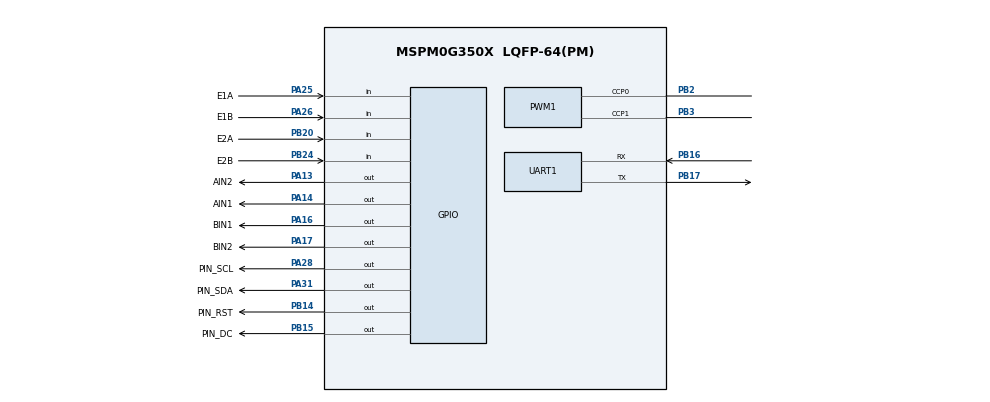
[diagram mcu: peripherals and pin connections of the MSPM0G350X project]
/**
 *
 * @cliArgs --device "MSPM0G350X" --part "Default" --package "LQFP-64(PM)" --product "mspm0_sdk@2.10.00.04"
 * @versions {"tool":"1.28.0+4696"}
 */

/**
 * Import the modules used in this configuration.
 */
const ADC12   = scripting.addModule("/ti/driverlib/ADC12", {}, false);
const ADC121  = ADC12.addInstance();
const DMA     = scripting.addModule("/ti/driverlib/DMA");
const GPIO    = scripting.addModule("/ti/driverlib/GPIO", {}, false);
const GPIO1   = GPIO.addInstance();
const GPIO2   = GPIO.addInstance();
const GPIO3   = GPIO.addInstance();
const GPIO4   = GPIO.addInstance();
const GPIO5   = GPIO.addInstance();
const GPIO6   = GPIO.addInstance();
const GPIO7   = GPIO.addInstance();
const GPIO8   = GPIO.addInstance();
const GPIO9   = GPIO.addInstance();
const GPIO10  = GPIO.addInstance();
const PWM     = scripting.addModule("/ti/driverlib/PWM", {}, false);
const PWM1    = PWM.addInstance();
const SYSCTL  = scripting.addModule("/ti/driverlib/SYSCTL");
const SYSTICK = scripting.addModule("/ti/driverlib/SYSTICK");
const TIMER   = scripting.addModule("/ti/driverlib/TIMER", {}, false);
const TIMER1  = TIMER.addInstance();
const UART    = scripting.addModule("/ti/driverlib/UART", {}, false);
const UART1   = UART.addInstance();

/**
 * Write custom configuration values to the imported modules.
 */
const divider7       = system.clockTree["PLL_PDIV"];
divider7.divideValue = 2;

const divider9       = system.clockTree["UDIV"];
divider9.divideValue = 2;

const multiplier2         = system.clockTree["PLL_QDIV"];
multiplier2.multiplyValue = 5;

const mux8       = system.clockTree["HSCLKMUX"];
mux8.inputSelect = "HSCLKMUX_SYSPLL2X";

ADC121.$name               = "ADC12_0";
ADC121.sampClkDiv          = "DL_ADC12_CLOCK_DIVIDE_8";
ADC121.repeatMode          = true;
ADC121.enabledInterrupts   = ["DL_ADC12_INTERRUPT_MEM0_RESULT_LOADED"];
ADC121.sampleTime0         = "2 us";
ADC121.adcPin0Config.$name = "ti_driverlib_gpio_GPIOPinGeneric0";

const Board = scripting.addModule("/ti/driverlib/Board", {}, false);

GPIO1.$name                         = "OLED_RST";
GPIO1.associatedPins[0].$name       = "PIN_RST";
GPIO1.associatedPins[0].pin.$assign = "PB14";

GPIO2.$name                         = "OLED_DC";
GPIO2.associatedPins[0].$name       = "PIN_DC";
GPIO2.associatedPins[0].pin.$assign = "PB15";

GPIO3.$name                         = "OLED_SCL";
GPIO3.associatedPins[0].$name       = "PIN_SCL";
GPIO3.associatedPins[0].pin.$assign = "PA28";

GPIO4.$name                         = "OLED_SDA";
GPIO4.associatedPins[0].$name       = "PIN_SDA";
GPIO4.associatedPins[0].pin.$assign = "PA31";

GPIO5.$name                         = "AIN";
GPIO5.port                          = "PORTA";
GPIO5.associatedPins.create(2);
GPIO5.associatedPins[0].$name       = "AIN1";
GPIO5.associatedPins[0].pin.$assign = "PA14";
GPIO5.associatedPins[1].$name       = "AIN2";
GPIO5.associatedPins[1].pin.$assign = "PA13";

GPIO6.$name                         = "BIN";
GPIO6.port                          = "PORTA";
GPIO6.associatedPins.create(2);
GPIO6.associatedPins[0].$name       = "BIN1";
GPIO6.associatedPins[0].pin.$assign = "PA16";
GPIO6.associatedPins[1].$name       = "BIN2";
GPIO6.associatedPins[1].pin.$assign = "PA17";

GPIO7.$name                               = "ENCODERA";
GPIO7.associatedPins.create(2);
GPIO7.associatedPins[0].$name             = "E1A";
GPIO7.associatedPins[0].direction         = "INPUT";
GPIO7.associatedPins[0].interruptEn       = true;
GPIO7.associatedPins[0].polarity          = "RISE";
GPIO7.associatedPins[0].interruptPriority = "0";
GPIO7.associatedPins[0].pin.$assign       = "PA25";
GPIO7.associatedPins[1].$name             = "E1B";
GPIO7.associatedPins[1].direction         = "INPUT";
GPIO7.associatedPins[1].interruptEn       = true;
GPIO7.associatedPins[1].polarity          = "RISE";
GPIO7.associatedPins[1].pin.$assign       = "PA26";

GPIO8.$name                               = "ENCODERB";
GPIO8.associatedPins.create(2);
GPIO8.associatedPins[0].$name             = "E2A";
GPIO8.associatedPins[0].direction         = "INPUT";
GPIO8.associatedPins[0].interruptEn       = true;
GPIO8.associatedPins[0].polarity          = "RISE";
GPIO8.associatedPins[0].interruptPriority = "0";
GPIO8.associatedPins[0].pin.$assign       = "PB20";
GPIO8.associatedPins[1].$name             = "E2B";
GPIO8.associatedPins[1].direction         = "INPUT";
GPIO8.associatedPins[1].interruptEn       = true;
GPIO8.associatedPins[1].polarity          = "RISE_FALL";
GPIO8.associatedPins[1].pin.$assign       = "PB24";

GPIO9.$name                         = "Gray_Address";
GPIO9.port                          = "PORTA";
GPIO9.portSegment                   = "Lower";
GPIO9.associatedPins.create(2);
GPIO9.associatedPins[0].$name       = "PIN_0";
GPIO9.associatedPins[0].assignedPin = "8";
GPIO9.associatedPins[1].$name       = "PIN_1";
GPIO9.associatedPins[1].assignedPin = "9";

GPIO10.$name                         = "Gray_Address_2";
GPIO10.port                          = "PORTA";
GPIO10.portSegment                   = "Upper";
GPIO10.associatedPins[0].$name       = "PIN_2";
GPIO10.associatedPins[0].assignedPin = "24";

PWM1.$name                      = "PWM_0";
PWM1.pwmMode                    = "EDGE_ALIGN_UP";
PWM1.timerStartTimer            = true;
PWM1.timerCount                 = 8000;
PWM1.peripheral.$assign         = "TIMA1";
PWM1.peripheral.ccp0Pin.$assign = "PB2";
PWM1.peripheral.ccp1Pin.$assign = "PB3";
PWM1.PWM_CHANNEL_0.$name        = "ti_driverlib_pwm_PWMTimerCC0";
PWM1.PWM_CHANNEL_1.$name        = "ti_driverlib_pwm_PWMTimerCC1";
PWM1.ccp0PinConfig.$name        = "ti_driverlib_gpio_GPIOPinGeneric3";
PWM1.ccp1PinConfig.$name        = "ti_driverlib_gpio_GPIOPinGeneric4";

SYSCTL.forceDefaultClkConfig = true;
SYSCTL.clockTreeEn           = true;

SYSTICK.periodEnable    = true;
SYSTICK.period          = 32000;
SYSTICK.interruptEnable = true;
SYSTICK.systickEnable   = true;

TIMER1.$name             = "TIMER_0";
TIMER1.timerClkPrescale  = 32;
TIMER1.timerMode         = "PERIODIC_UP";
TIMER1.interrupts        = ["ZERO"];
TIMER1.interruptPriority = "1";
TIMER1.timerPeriod       = "10 ms";

UART1.$name                            = "UART_K230";
UART1.targetBaudRate                   = 115200;
UART1.enabledInterrupts                = ["RX"];
UART1.peripheral.$assign               = "UART2";
UART1.peripheral.rxPin.$assign         = "PB16";
UART1.peripheral.txPin.$assign         = "PB17";
UART1.txPinConfig.direction            = scripting.forceWrite("OUTPUT");
UART1.txPinConfig.hideOutputInversion  = scripting.forceWrite(false);
UART1.txPinConfig.onlyInternalResistor = scripting.forceWrite(false);
UART1.txPinConfig.passedPeripheralType = scripting.forceWrite("Digital");
UART1.txPinConfig.$name                = "ti_driverlib_gpio_GPIOPinGeneric5";
UART1.rxPinConfig.hideOutputInversion  = scripting.forceWrite(false);
UART1.rxPinConfig.onlyInternalResistor = scripting.forceWrite(false);
UART1.rxPinConfig.passedPeripheralType = scripting.forceWrite("Digital");
UART1.rxPinConfig.$name                = "ti_driverlib_gpio_GPIOPinGeneric6";

/**
 * Pinmux solution for unlocked pins/peripherals. This ensures that minor changes to the automatic solver in a future
 * version of the tool will not impact the pinmux you originally saw.  These lines can be completely deleted in order to
 * re-solve from scratch.
 */
ADC121.peripheral.$suggestSolution            = "ADC0";
ADC121.peripheral.adcPin0.$suggestSolution    = "PA27";
Board.peripheral.$suggestSolution             = "DEBUGSS";
Board.peripheral.swclkPin.$suggestSolution    = "PA20";
Board.peripheral.swdioPin.$suggestSolution    = "PA19";
GPIO9.associatedPins[0].pin.$suggestSolution  = "PA8";
GPIO9.associatedPins[1].pin.$suggestSolution  = "PA9";
GPIO10.associatedPins[0].pin.$suggestSolution = "PA24";
TIMER1.peripheral.$suggestSolution            = "TIMA0";
